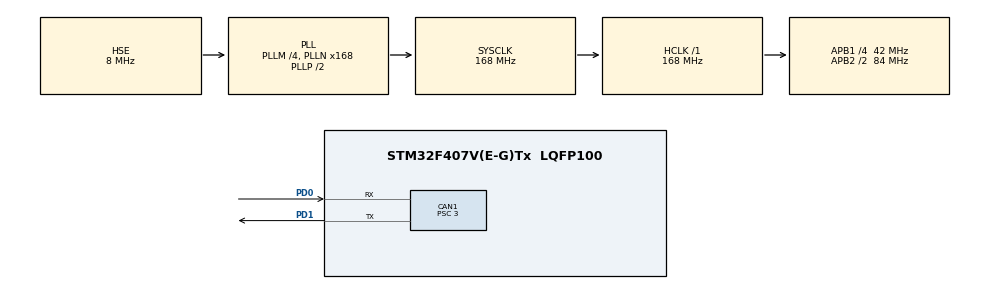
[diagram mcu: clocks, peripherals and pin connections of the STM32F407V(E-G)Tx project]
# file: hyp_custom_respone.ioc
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CAN1.BS1=CAN_BS1_12TQ
CAN1.CalculateBaudRate=1000000
CAN1.CalculateTimeBit=1000
CAN1.CalculateTimeQuantum=71.42857142857143
CAN1.Prescaler=3
Mcu.Family=STM32F4
Mcu.Name=STM32F407V(E-G)Tx
Mcu.Package=LQFP100
NVIC.CAN1_RX0_IRQn=true\:0\:0\:false\:false\:true\:true\:true\:true
NVIC.PriorityGroup=NVIC_PRIORITYGROUP_4
PA13.Mode=Serial_Wire
PA13.Signal=SYS_JTMS-SWDIO
PA14.Mode=Serial_Wire
PA14.Signal=SYS_JTCK-SWCLK
PD0.GPIO_PuPd=GPIO_PULLUP
PD0.Mode=CAN_Activate
PD0.Signal=CAN1_RX
PD1.Mode=CAN_Activate
PD1.Signal=CAN1_TX
PH0-OSC_IN.Mode=HSE-External-Oscillator
PH0-OSC_IN.Signal=RCC_OSC_IN
PH1-OSC_OUT.Mode=HSE-External-Oscillator
PH1-OSC_OUT.Signal=RCC_OSC_OUT
ProjectManager.HeapSize=0x200
ProjectManager.StackSize=0x400
ProjectManager.TargetToolchain=STM32CubeIDE
RCC.48MHZClocksFreq_Value=84000000
RCC.AHBFreq_Value=168000000
RCC.APB1CLKDivider=RCC_HCLK_DIV4
RCC.APB1Freq_Value=42000000
RCC.APB1TimFreq_Value=84000000
RCC.APB2CLKDivider=RCC_HCLK_DIV2
RCC.APB2Freq_Value=84000000
RCC.APB2TimFreq_Value=168000000
RCC.CortexFreq_Value=168000000
RCC.HCLKFreq_Value=168000000
RCC.HSE_VALUE=8000000
RCC.HSI_VALUE=16000000
RCC.LSE_VALUE=32768
RCC.PLLM=4
RCC.PLLN=168
RCC.PLLSourceVirtual=RCC_PLLSOURCE_HSE
RCC.SYSCLKFreq_VALUE=168000000
RCC.SYSCLKSource=RCC_SYSCLKSOURCE_PLLCLK
RCC.VCOOutputFreq_Value=336000000
board=custom

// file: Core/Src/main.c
/* USER CODE BEGIN Header */
/**
  ******************************************************************************
  * @file           : main.c
  * @brief          : Main program body
  ******************************************************************************
  * @attention
  *
  * Copyright (c) 2025 STMicroelectronics.
  * All rights reserved.
  *
  * This software is licensed under terms that can be found in the LICENSE file
  * in the root directory of this software component.
  * If no LICENSE file comes with this software, it is provided AS-IS.
  *
  ******************************************************************************
  */
/* USER CODE END Header */
#include "main.h"

/* USER CODE BEGIN Includes */
#include "canard.h"
#include "canard_internals.h"
#include "string.h"
#include "hyp.msg.BatteryStatus_Hyp.h"
#include "hyp.msg.GetNodeInfor_Hyp.h"
#include "hyp.msg.HeartBeat_Hyp.h"
/* USER CODE END Includes */

CAN_HandleTypeDef hcan1;

void SystemClock_Config(void);
static void MX_GPIO_Init(void);
static void MX_CAN1_Init(void);
/* USER CODE BEGIN PFP */
uint8_t canard_memory_pool[1024];
CanardInstance canard;

struct hyp_msg_BatteryStatus_Hyp req;

//debug
uint32_t count = 0;
uint32_t count1 = 0;
volatile int should_accept_called = 0;
volatile int should_accept_last_type = 0;
volatile int should_accept_last_src = 0;
volatile int should_accept_last_id = 0;
/* USER CODE END PFP */

/* USER CODE BEGIN 0 */
void HAL_CAN_RxFifo0MsgPendingCallback(CAN_HandleTypeDef *hcan)
{
    CAN_RxHeaderTypeDef rxHeader;
    uint8_t rxData[8];
    count1++;
    if (HAL_CAN_GetRxMessage(hcan, CAN_RX_FIFO0, &rxHeader, rxData) == HAL_OK) {
        CanardCANFrame frame;
        frame.id = rxHeader.ExtId;
        if (rxHeader.IDE == CAN_ID_EXT)
            frame.id |= (1UL << 31);

        frame.data_len = rxHeader.DLC;
        memcpy(frame.data, rxData, rxHeader.DLC);
        frame.iface_id = 0;

        canardHandleRxFrame(&canard, &frame, HAL_GetTick() * 1000ULL);
    }
}
bool should_accept(const CanardInstance* ins, uint64_t* out_sig, uint16_t data_type_id,
                   CanardTransferType transfer_type, uint8_t source_node_id) {
	should_accept_last_type = transfer_type;
	should_accept_last_src = source_node_id;
	should_accept_last_id = data_type_id;
    if (data_type_id == 232 && transfer_type == CanardTransferTypeRequest) {
        *out_sig = HYP_MSG_BATTERYSTATUS_HYP_SIGNATURE;
        return true;
    }
    return false;
}

void on_reception(CanardInstance* ins, CanardRxTransfer* transfer)
{
	if (transfer->data_type_id == 232 && transfer->transfer_type == CanardTransferTypeRequest)
	{
		count++;
		hyp_msg_BatteryStatus_Hyp_decode(transfer,&req);
		if (strncmp((char*)req.name.data, "Get_batt", req.name.len) == 0)
		{
			struct hyp_msg_BatteryStatus_Hyp value;
			value.current = 4;
			value.voltage = 22;
			value.name.len = strlen("HYPMOTION_BATT1");
			memcpy(value.name.data, "HYPMOTION_BATT1", value.name.len);
			uint8_t buffer[HYP_MSG_BATTERYSTATUS_HYP_MAX_SIZE];
			uint32_t len = hyp_msg_BatteryStatus_Hyp_encode(&value, buffer
#if CANARD_ENABLE_TAO_OPTION
		, true
#endif
		    );
			uint8_t tid = transfer->transfer_id;
			canardRequestOrRespond(&canard, transfer->source_node_id,
					HYP_MSG_BATTERYSTATUS_HYP_SIGNATURE,
					HYP_MSG_BATTERYSTATUS_HYP_ID,
					&tid, CANARD_TRANSFER_PRIORITY_LOW,
					CanardResponse, buffer, len);
		}
	}
}
void tx_frame(void)
{
	CanardCANFrame* txf = NULL;
	while ((txf = canardPeekTxQueue(&canard)) != NULL)
	{
		if (HAL_CAN_GetTxMailboxesFreeLevel(&hcan1) > 0)
		{
			CAN_TxHeaderTypeDef txHeader;
			memset(&txHeader, 0, sizeof(txHeader));
			txHeader.IDE = CAN_ID_EXT;
			txHeader.ExtId = txf->id & 0x1FFFFFFF;
			txHeader.RTR = CAN_RTR_DATA;
			txHeader.DLC = txf->data_len;
			txHeader.TransmitGlobalTime = DISABLE;

			uint32_t txMailbox;
			if (HAL_CAN_AddTxMessage(&hcan1, &txHeader, (uint8_t*)txf->data, &txMailbox) == HAL_OK)
			{
					canardPopTxQueue(&canard);
			}
			else
			{
					break;
			}
		}
		else
		{
				break;
		}
	}
	HAL_Delay(1);
}

void config_filter(void)
{
		//------------filer-------------//
	CAN_FilterTypeDef sFilterConfig;
	sFilterConfig.FilterBank = 0;
	sFilterConfig.FilterMode = CAN_FILTERMODE_IDMASK;
	sFilterConfig.FilterScale = CAN_FILTERSCALE_32BIT;
	sFilterConfig.FilterIdHigh = 0;
	sFilterConfig.FilterIdLow  = 0;
	sFilterConfig.FilterMaskIdHigh = 0;
	sFilterConfig.FilterMaskIdLow  = 0;
	sFilterConfig.FilterFIFOAssignment = CAN_FILTER_FIFO0;
	sFilterConfig.FilterActivation = ENABLE;
	HAL_CAN_ConfigFilter(&hcan1, &sFilterConfig);
}
/* USER CODE END 0 */

int main(void)
{

  /* MCU Configuration--------------------------------------------------------*/

  /* Reset of all peripherals, Initializes the Flash interface and the Systick. */
  HAL_Init();

  /* Configure the system clock */
  SystemClock_Config();

  /* Initialize all configured peripherals */
  MX_GPIO_Init();
  MX_CAN1_Init();
  /* USER CODE BEGIN 2 */
  HAL_CAN_Start(&hcan1);
  HAL_CAN_ActivateNotification(&hcan1, CAN_IT_RX_FIFO0_MSG_PENDING);
  canardInit(&canard,
	 canard_memory_pool,
	 sizeof(canard_memory_pool),
	 on_reception,
	 should_accept,
	 NULL);
  canardSetLocalNodeID(&canard, 11);
  config_filter();
  /* USER CODE END 2 */

  /* Infinite loop */
  /* USER CODE BEGIN WHILE */
  while (1)
  {
	  tx_frame();
    /* USER CODE END WHILE */

  }
}

void SystemClock_Config(void)
{
  RCC_OscInitTypeDef RCC_OscInitStruct = {0};
  RCC_ClkInitTypeDef RCC_ClkInitStruct = {0};

  /** Configure the main internal regulator output voltage
  */
  __HAL_RCC_PWR_CLK_ENABLE();
  __HAL_PWR_VOLTAGESCALING_CONFIG(PWR_REGULATOR_VOLTAGE_SCALE1);

  /** Initializes the RCC Oscillators according to the specified parameters
  * in the RCC_OscInitTypeDef structure.
  */
  RCC_OscInitStruct.OscillatorType = RCC_OSCILLATORTYPE_HSE;
  RCC_OscInitStruct.HSEState = RCC_HSE_ON;
  RCC_OscInitStruct.PLL.PLLState = RCC_PLL_ON;
  RCC_OscInitStruct.PLL.PLLSource = RCC_PLLSOURCE_HSE;
  RCC_OscInitStruct.PLL.PLLM = 4;
  RCC_OscInitStruct.PLL.PLLN = 168;
  RCC_OscInitStruct.PLL.PLLP = RCC_PLLP_DIV2;
  RCC_OscInitStruct.PLL.PLLQ = 4;
  if (HAL_RCC_OscConfig(&RCC_OscInitStruct) != HAL_OK)
  {
    Error_Handler();
  }

  /** Initializes the CPU, AHB and APB buses clocks
  */
  RCC_ClkInitStruct.ClockType = RCC_CLOCKTYPE_HCLK|RCC_CLOCKTYPE_SYSCLK
                              |RCC_CLOCKTYPE_PCLK1|RCC_CLOCKTYPE_PCLK2;
  RCC_ClkInitStruct.SYSCLKSource = RCC_SYSCLKSOURCE_PLLCLK;
  RCC_ClkInitStruct.AHBCLKDivider = RCC_SYSCLK_DIV1;
  RCC_ClkInitStruct.APB1CLKDivider = RCC_HCLK_DIV4;
  RCC_ClkInitStruct.APB2CLKDivider = RCC_HCLK_DIV2;

  if (HAL_RCC_ClockConfig(&RCC_ClkInitStruct, FLASH_LATENCY_5) != HAL_OK)
  {
    Error_Handler();
  }
}

static void MX_CAN1_Init(void)
{

  hcan1.Instance = CAN1;
  hcan1.Init.Prescaler = 3;
  hcan1.Init.Mode = CAN_MODE_NORMAL;
  hcan1.Init.SyncJumpWidth = CAN_SJW_1TQ;
  hcan1.Init.TimeSeg1 = CAN_BS1_12TQ;
  hcan1.Init.TimeSeg2 = CAN_BS2_1TQ;
  hcan1.Init.TimeTriggeredMode = DISABLE;
  hcan1.Init.AutoBusOff = DISABLE;
  hcan1.Init.AutoWakeUp = DISABLE;
  hcan1.Init.AutoRetransmission = DISABLE;
  hcan1.Init.ReceiveFifoLocked = DISABLE;
  hcan1.Init.TransmitFifoPriority = DISABLE;
  if (HAL_CAN_Init(&hcan1) != HAL_OK)
  {
    Error_Handler();
  }

}

static void MX_GPIO_Init(void)
{

  /* GPIO Ports Clock Enable */
  __HAL_RCC_GPIOH_CLK_ENABLE();
  __HAL_RCC_GPIOA_CLK_ENABLE();
  __HAL_RCC_GPIOD_CLK_ENABLE();

}

void Error_Handler(void)
{
  __disable_irq();
  while (1)
  {
  }
}
